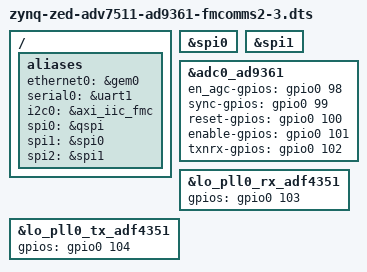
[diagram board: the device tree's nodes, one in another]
/*
 * CAUTION: This file is automatically generated by Xilinx.
 * Version:  
 * Today is: Fri Jan 19 15:56:45 2024
 */


/dts-v1/;
#include "zynq-zed.dtsi"
#include "zynq-zed-adv7511.dtsi"
#include "pcw.dtsi"
/ {
	aliases {
		ethernet0 = &gem0;
		serial0 = &uart1;
		i2c0 = &axi_iic_fmc;
		spi0 = &qspi;
		spi1 = &spi0;
		spi2 = &spi1;
	};
};

&spi0 {
	status = "okay";
};

&spi1 {
	status = "okay";
};

#define fmc_spi spi0
#define pmod_spi spi1

#include "adi-fmcomms2.dtsi"
#include "adi-fmcomms3-up-down-converter.dtsi"

&adc0_ad9361 {
	en_agc-gpios = <&gpio0 98 0>;
	sync-gpios = <&gpio0 99 0>;
	reset-gpios = <&gpio0 100 0>;
	enable-gpios = <&gpio0 101 0>;
	txnrx-gpios = <&gpio0 102 0>;
};

&lo_pll0_rx_adf4351 {
	gpios = <&gpio0 103 0>;
};

&lo_pll0_tx_adf4351 {
	gpios = <&gpio0 104 0>;
};
